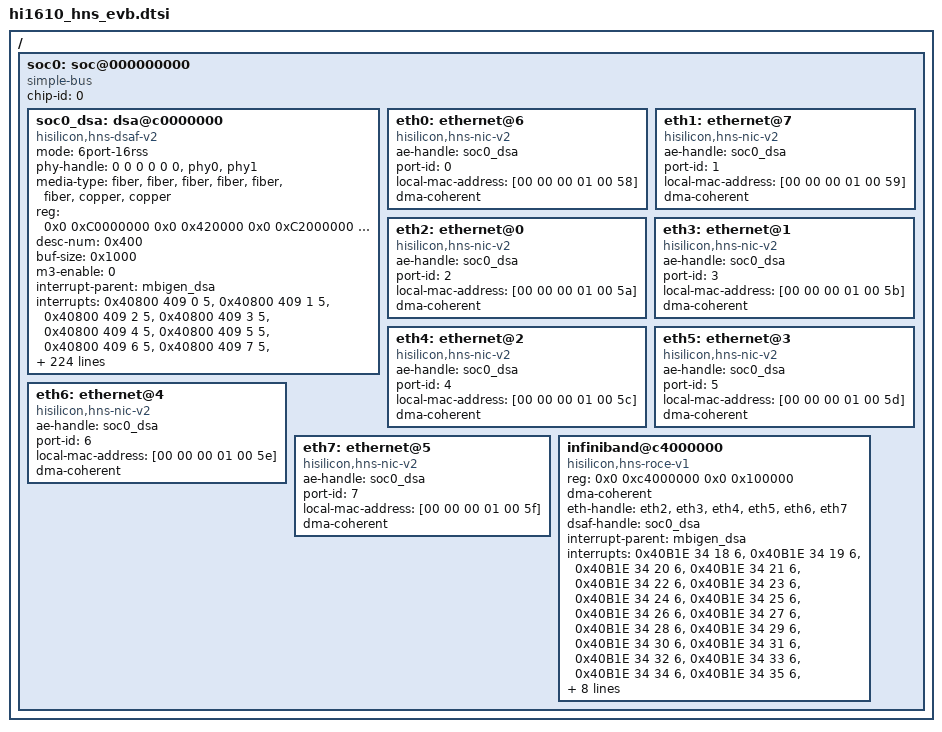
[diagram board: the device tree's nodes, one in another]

/*
 * dtsi file for Hisilicon Hi1610 hns driver
 */

/ {
	soc0: soc@000000000 {
		#address-cells = <2>;
		#size-cells = <2>;
		device_type = "soc";
		compatible = "simple-bus";
		ranges = <0x0 0x0 0x0 0x0 0x1 0x0>;
		chip-id = <0>;

		soc0_dsa: dsa@c0000000 {
			compatible = "hisilicon,hns-dsaf-v2";
			mode = "6port-16rss";
			phy-handle = <0 0 0 0 0 0 &phy0 &phy1>;
			media-type = "fiber", "fiber", "fiber", "fiber",
				"fiber", "fiber", "copper", "copper";
			reg = <0x0 0xC0000000 0x0 0x420000
				0x0 0xC2000000 0x0 0x300000
				0x0 0xc5000000 0x0 0x890000
				0x0 0xc7000000 0x0 0x60000
				0x0 0x78000010 0x0 0x100>;
			desc-num = <0x400>;
			buf-size = <0x1000>;
			m3-enable = <0>;

		interrupt-parent = <&mbigen_dsa>;
		interrupts =
		<0x40800 409 0 5>,<0x40800 409 1 5>,
		<0x40800 409 2 5>,<0x40800 409 3 5>,
		<0x40800 409 4 5>,<0x40800 409 5 5>,
		<0x40800 409 6 5>,<0x40800 409 7 5>,
		<0x40800 409 8 5>,<0x40800 409 9 5>,
		<0x40800 409 10 5>,<0x40800 409 11 5>,
		<0x40800 409 12 5>,
		<0x40800 409 0 7>,<0x40800 409 1 7>,
		<0x40800 409 2 7>,<0x40800 409 3 7>,
		<0x40800 409 4 7>,<0x40800 409 5 7>,
		<0x40800 409 6 7>,<0x40800 409 7 7>,
		<0x40800 409 8 7>,<0x40800 409 9 7>,
		<0x40800 409 10 7>,<0x40800 409 11 7>,
		/* index 25/26/27 ring0 tx/rx/doorbell*/
		<0x40800 409 0 8>,<0x40800 409 1 8>,<0x40800 409 2 8>,
		<0x40800 409 3 8>,<0x40800 409 4 8>,<0x40800 409 5 8>,
		<0x40800 409 6 8>,<0x40800 409 7 8>,<0x40800 409 8 8>,
		<0x40800 409 9 8>,<0x40800 409 10 8>,<0x40800 409 11 8>,
		<0x40800 409 12 8>,<0x40800 409 13 8>,<0x40800 409 14 8>,
		<0x40800 409 15 8>,<0x40800 409 16 8>,<0x40800 409 17 8>,
		<0x40800 409 18 8>,<0x40800 409 19 8>,<0x40800 409 20 8>,
		<0x40800 409 21 8>,<0x40800 409 22 8>,<0x40800 409 23 8>,
		<0x40800 409 24 8>,<0x40800 409 25 8>,<0x40800 409 26 8>,
		<0x40800 409 27 8>,<0x40800 409 28 8>,<0x40800 409 29 8>,
		<0x40800 409 30 8>,<0x40800 409 31 8>,<0x40800 409 32 8>,
		<0x40800 409 33 8>,<0x40800 409 34 8>,<0x40800 409 35 8>,
		<0x40800 409 36 8>,<0x40800 409 37 8>,<0x40800 409 38 8>,
		<0x40800 409 39 8>,<0x40800 409 40 8>,<0x40800 409 41 8>,
		<0x40800 409 42 8>,<0x40800 409 43 8>,<0x40800 409 44 8>,
		<0x40800 409 45 8>,<0x40800 409 46 8>,<0x40800 409 47 8>,
		<0x40800 409 48 8>,<0x40800 409 49 8>,<0x40800 409 50 8>,
		<0x40800 409 51 8>,<0x40800 409 52 8>,<0x40800 409 53 8>,
		<0x40800 409 54 8>,<0x40800 409 55 8>,<0x40800 409 56 8>,
		<0x40800 409 57 8>,<0x40800 409 58 8>,<0x40800 409 59 8>,
		<0x40800 409 60 8>,<0x40800 409 61 8>,<0x40800 409 62 8>,
		<0x40800 409 63 8>,<0x40800 409 64 8>,<0x40800 409 65 8>,
		<0x40800 409 66 8>,<0x40800 409 67 8>,<0x40800 409 68 8>,
		<0x40800 409 69 8>,<0x40800 409 70 8>,<0x40800 409 71 8>,
		<0x40800 409 72 8>,<0x40800 409 73 8>,<0x40800 409 74 8>,
		<0x40800 409 75 8>,<0x40800 409 76 8>,<0x40800 409 77 8>,
		<0x40800 409 78 8>,<0x40800 409 79 8>,<0x40800 409 80 8>,
		<0x40800 409 81 8>,<0x40800 409 82 8>,<0x40800 409 83 8>,
		<0x40800 409 84 8>,<0x40800 409 85 8>,<0x40800 409 86 8>,
		<0x40800 409 87 8>,<0x40800 409 88 8>,<0x40800 409 89 8>,
		<0x40800 409 90 8>,<0x40800 409 91 8>,<0x40800 409 92 8>,
		<0x40800 409 93 8>,<0x40800 409 94 8>,<0x40800 409 95 8>,
		<0x40800 409 96 8>,<0x40800 409 97 8>,<0x40800 409 98 8>,
		<0x40800 409 99 8>,<0x40800 409 100 8>,<0x40800 409 101 8>,
		<0x40800 409 102 8>,<0x40800 409 103 8>,<0x40800 409 104 8>,
		<0x40800 409 105 8>,<0x40800 409 106 8>,<0x40800 409 107 8>,
		<0x40800 409 108 8>,<0x40800 409 109 8>,<0x40800 409 110 8>,
		<0x40800 409 111 8>,<0x40800 409 112 8>,<0x40800 409 113 8>,
		<0x40800 409 114 8>,<0x40800 409 115 8>,<0x40800 409 116 8>,
		<0x40800 409 117 8>,<0x40800 409 118 8>,<0x40800 409 119 8>,
		<0x40800 409 120 8>,<0x40800 409 121 8>,<0x40800 409 122 8>,
		<0x40800 409 123 8>,<0x40800 409 124 8>,<0x40800 409 125 8>,
		<0x40800 409 126 8>,<0x40800 409 127 8>,<0x40800 409 0 9>,
		<0x40800 409 1 9>,<0x40800 409 2 9>,<0x40800 409 3 9>,
		<0x40800 409 4 9>,<0x40800 409 5 9>,<0x40800 409 6 9>,
		<0x40800 409 7 9>,<0x40800 409 8 9>,<0x40800 409 9 9>,
		<0x40800 409 10 9>,<0x40800 409 11 9>,<0x40800 409 12 9>,
		<0x40800 409 13 9>,<0x40800 409 14 9>,<0x40800 409 15 9>,
		<0x40800 409 16 9>,<0x40800 409 17 9>,<0x40800 409 18 9>,
		<0x40800 409 19 9>,<0x40800 409 20 9>,<0x40800 409 21 9>,
		<0x40800 409 22 9>,<0x40800 409 23 9>,<0x40800 409 24 9>,
		<0x40800 409 25 9>,<0x40800 409 26 9>,<0x40800 409 27 9>,
		<0x40800 409 28 9>,<0x40800 409 29 9>,<0x40800 409 30 9>,
		<0x40800 409 31 9>,<0x40800 409 32 9>,<0x40800 409 33 9>,
		<0x40800 409 34 9>,<0x40800 409 35 9>,<0x40800 409 36 9>,
		<0x40800 409 37 9>,<0x40800 409 38 9>,<0x40800 409 39 9>,
		<0x40800 409 40 9>,<0x40800 409 41 9>,<0x40800 409 42 9>,
		<0x40800 409 43 9>,<0x40800 409 44 9>,<0x40800 409 45 9>,
		<0x40800 409 46 9>,<0x40800 409 47 9>,<0x40800 409 48 9>,
		<0x40800 409 49 9>,<0x40800 409 50 9>,<0x40800 409 51 9>,
		<0x40800 409 52 9>,<0x40800 409 53 9>,<0x40800 409 54 9>,
		<0x40800 409 55 9>,<0x40800 409 56 9>,<0x40800 409 57 9>,
		<0x40800 409 58 9>,<0x40800 409 59 9>,<0x40800 409 60 9>,
		<0x40800 409 61 9>,<0x40800 409 62 9>,<0x40800 409 63 9>,
		<0x40800 409 64 9>,<0x40800 409 65 9>,<0x40800 409 66 9>,
		<0x40800 409 67 9>,<0x40800 409 68 9>,<0x40800 409 69 9>,
		<0x40800 409 70 9>,<0x40800 409 71 9>,<0x40800 409 72 9>,
		<0x40800 409 73 9>,<0x40800 409 74 9>,<0x40800 409 75 9>,
		<0x40800 409 76 9>,<0x40800 409 77 9>,<0x40800 409 78 9>,
		<0x40800 409 79 9>,<0x40800 409 80 9>,<0x40800 409 81 9>,
		<0x40800 409 82 9>,<0x40800 409 83 9>,<0x40800 409 84 9>,
		<0x40800 409 85 9>,<0x40800 409 86 9>,<0x40800 409 87 9>,
		<0x40800 409 88 9>,<0x40800 409 89 9>,<0x40800 409 90 9>,
		<0x40800 409 91 9>,<0x40800 409 92 9>,<0x40800 409 93 9>,
		<0x40800 409 94 9>,<0x40800 409 95 9>,<0x40800 409 96 9>,
		<0x40800 409 97 9>,<0x40800 409 98 9>,<0x40800 409 99 9>,
		<0x40800 409 100 9>,<0x40800 409 101 9>,<0x40800 409 102 9>,
		<0x40800 409 103 9>,<0x40800 409 104 9>,<0x40800 409 105 9>,
		<0x40800 409 106 9>,<0x40800 409 107 9>,<0x40800 409 108 9>,
		<0x40800 409 109 9>,<0x40800 409 110 9>,<0x40800 409 111 9>,
		<0x40800 409 112 9>,<0x40800 409 113 9>,<0x40800 409 114 9>,
		<0x40800 409 115 9>,<0x40800 409 116 9>,<0x40800 409 117 9>,
		<0x40800 409 118 9>,<0x40800 409 119 9>,<0x40800 409 120 9>,
		<0x40800 409 121 9>,<0x40800 409 122 9>,<0x40800 409 123 9>,
		<0x40800 409 124 9>,<0x40800 409 125 9>,<0x40800 409 126 9>,
		<0x40800 409 127 9>,<0x40800 409 0 10>,<0x40800 409 1 10>,
		<0x40800 409 2 10>,<0x40800 409 3 10>,<0x40800 409 4 10>,
		<0x40800 409 5 10>,<0x40800 409 6 10>,<0x40800 409 7 10>,
		<0x40800 409 8 10>,<0x40800 409 9 10>,<0x40800 409 10 10>,
		<0x40800 409 11 10>,<0x40800 409 12 10>,<0x40800 409 13 10>,
		<0x40800 409 14 10>,<0x40800 409 15 10>,<0x40800 409 16 10>,
		<0x40800 409 17 10>,<0x40800 409 18 10>,<0x40800 409 19 10>,
		<0x40800 409 20 10>,<0x40800 409 21 10>,<0x40800 409 22 10>,
		<0x40800 409 23 10>,<0x40800 409 24 10>,<0x40800 409 25 10>,
		<0x40800 409 26 10>,<0x40800 409 27 10>,<0x40800 409 28 10>,
		<0x40800 409 29 10>,<0x40800 409 30 10>,<0x40800 409 31 10>,
		<0x40800 409 32 10>,<0x40800 409 33 10>,<0x40800 409 34 10>,
		<0x40800 409 35 10>,<0x40800 409 36 10>,<0x40800 409 37 10>,
		<0x40800 409 38 10>,<0x40800 409 39 10>,<0x40800 409 40 10>,
		<0x40800 409 41 10>,<0x40800 409 42 10>,<0x40800 409 43 10>,
		<0x40800 409 44 10>,<0x40800 409 45 10>,<0x40800 409 46 10>,
		<0x40800 409 47 10>,<0x40800 409 48 10>,<0x40800 409 49 10>,
		<0x40800 409 50 10>,<0x40800 409 51 10>,<0x40800 409 52 10>,
		<0x40800 409 53 10>,<0x40800 409 54 10>,<0x40800 409 55 10>,
		<0x40800 409 56 10>,<0x40800 409 57 10>,<0x40800 409 58 10>,
		<0x40800 409 59 10>,<0x40800 409 60 10>,<0x40800 409 61 10>,
		<0x40800 409 62 10>,<0x40800 409 63 10>,<0x40800 409 64 10>,
		<0x40800 409 65 10>,<0x40800 409 66 10>,<0x40800 409 67 10>,
		<0x40800 409 68 10>,<0x40800 409 69 10>,<0x40800 409 70 10>,
		<0x40800 409 71 10>,<0x40800 409 72 10>,<0x40800 409 73 10>,
		<0x40800 409 74 10>,<0x40800 409 75 10>,<0x40800 409 76 10>,
		<0x40800 409 77 10>,<0x40800 409 78 10>,<0x40800 409 79 10>,
		<0x40800 409 80 10>,<0x40800 409 81 10>,<0x40800 409 82 10>,
		<0x40800 409 83 10>,<0x40800 409 84 10>,<0x40800 409 85 10>,
		<0x40800 409 86 10>,<0x40800 409 87 10>,<0x40800 409 88 10>,
		<0x40800 409 89 10>,<0x40800 409 90 10>,<0x40800 409 91 10>,
		<0x40800 409 92 10>,<0x40800 409 93 10>,<0x40800 409 94 10>,
		<0x40800 409 95 10>,<0x40800 409 96 10>,<0x40800 409 97 10>,
		<0x40800 409 98 10>,<0x40800 409 99 10>,<0x40800 409 100 10>,
		<0x40800 409 101 10>,<0x40800 409 102 10>,<0x40800 409 103 10>,
		<0x40800 409 104 10>,<0x40800 409 105 10>,<0x40800 409 106 10>,
		<0x40800 409 107 10>,<0x40800 409 108 10>,<0x40800 409 109 10>,
		<0x40800 409 110 10>,<0x40800 409 111 10>,<0x40800 409 112 10>,
		<0x40800 409 113 10>,<0x40800 409 114 10>,<0x40800 409 115 10>,
		<0x40800 409 116 10>,<0x40800 409 117 10>,<0x40800 409 118 10>,
		<0x40800 409 119 10>,<0x40800 409 120 10>,<0x40800 409 121 10>,
		<0x40800 409 122 10>,<0x40800 409 123 10>,<0x40800 409 124 10>,
		<0x40800 409 125 10>,<0x40800 409 126 10>,<0x40800 409 127 10>,
		/* index = 409 debug0 tx/rx */
		<0x40b1c 9 0 6>,<0x40b1c 9 1 6>,
		<0x40b1c 9 2 6>,<0x40b1c 9 3 6>,
		<0x40b1c 9 4 6>,<0x40b1c 9 5 6>,
		<0x40b1c 9 6 6>,<0x40b1c 9 7 6>,
		<0x40b1c 9 8 6>,
		/* index = 418 debug1 tx/rx */
		<0x40b1d 9 9 6>,<0x40b1d 9 10 6>,
		<0x40b1d 9 11 6>,<0x40b1d 9 12 6>,
		<0x40b1d 9 13 6>,<0x40b1d 9 14 6>,
		<0x40b1d 9 15 6>,<0x40b1d 9 16 6>,
		<0x40b1d 9 17 6>,
		/* xbar int index=427 */
		<0x40b1f 18 51 6>,<0x40b1f 18 52 6>,
		<0x40b1f 18 53 6>,<0x40b1f 18 54 6>,
		<0x40b1f 18 55 6>,<0x40b1f 18 56 6>,
		<0x40b1f 18 57 6>,<0x40b1f 18 58 6>,
		<0x40b1f 18 59 6>,<0x40b1f 18 60 6>,
		<0x40b1f 18 61 6>,<0x40b1f 18 62 6>,
		<0x40b1f 18 63 6>,<0x40b1f 18 64 6>,
		<0x40b1f 18 65 6>,<0x40b1f 18 66 6>,
		<0x40b1f 18 67 6>,<0x40b1f 18 68 6>,
		<0x40881 12 13 5>, /* GE0 int index=445 */
		<0x40881 12 14 5>,
		<0x40881 12 15 5>,
		<0x40881 12 16 5>,
		<0x40881 12 17 5>,
		<0x40881 12 18 5>,
		<0x40881 12 19 5>, /* XGE0 int index=451 */
		<0x40881 12 20 5>,
		<0x40881 12 21 5>,
		<0x40881 12 22 5>,
		<0x40881 12 23 5>,
		<0x40881 12 24 5>;
			dma-coherent;
		};

		eth0:ethernet@6 {
			compatible = "hisilicon,hns-nic-v2";
			ae-handle = <&soc0_dsa>;
			port-id = <0>;
			local-mac-address = [00 00 00 01 00 58];
			dma-coherent;
		};

		eth1:ethernet@7 {
			compatible = "hisilicon,hns-nic-v2";
			ae-handle = <&soc0_dsa>;
			port-id = <1>;
			local-mac-address = [00 00 00 01 00 59];
			dma-coherent;
		};

		eth2:ethernet@0 {
			compatible = "hisilicon,hns-nic-v2";
			ae-handle = <&soc0_dsa>;
			port-id = <2>;
			local-mac-address = [00 00 00 01 00 5a];
			dma-coherent;
		};

		eth3:ethernet@1 {
			compatible = "hisilicon,hns-nic-v2";
			ae-handle = <&soc0_dsa>;
			port-id = <3>;
			local-mac-address = [00 00 00 01 00 5b];
			dma-coherent;
		};

		eth4:ethernet@2 {
			compatible = "hisilicon,hns-nic-v2";
			ae-handle = <&soc0_dsa>;
			port-id = <4>;
			local-mac-address = [00 00 00 01 00 5c];
			dma-coherent;
		};

		eth5:ethernet@3 {
			compatible = "hisilicon,hns-nic-v2";
			ae-handle = <&soc0_dsa>;
			port-id = <5>;
			local-mac-address = [00 00 00 01 00 5d];
			dma-coherent;
		};

		eth6:ethernet@4 {
			compatible = "hisilicon,hns-nic-v2";
			ae-handle = <&soc0_dsa>;
			port-id = <6>;
			local-mac-address = [00 00 00 01 00 5e];
			dma-coherent;
		};

		eth7:ethernet@5 {
			compatible = "hisilicon,hns-nic-v2";
			ae-handle = <&soc0_dsa>;
			port-id = <7>;
			local-mac-address = [00 00 00 01 00 5f];
			dma-coherent;
		};

		infiniband@c4000000 {
			compatible = "hisilicon,hns-roce-v1";
			reg = <0x0 0xc4000000 0x0 0x100000>;
			dma-coherent;
			eth-handle = <&eth2 &eth3 &eth4 &eth5 &eth6 &eth7>;
			dsaf-handle = <&soc0_dsa>;
			#address-cells = <2>;
			#size-cells = <2>;
			interrupt-parent = <&mbigen_dsa>;
			interrupts = <0x40B1E 34 18 6>,
					<0x40B1E 34 19 6>,
					<0x40B1E 34 20 6>,
					<0x40B1E 34 21 6>,
					<0x40B1E 34 22 6>,
					<0x40B1E 34 23 6>,
					<0x40B1E 34 24 6>,
					<0x40B1E 34 25 6>,
					<0x40B1E 34 26 6>,
					<0x40B1E 34 27 6>,
					<0x40B1E 34 28 6>,
					<0x40B1E 34 29 6>,
					<0x40B1E 34 30 6>,
					<0x40B1E 34 31 6>,
					<0x40B1E 34 32 6>,
					<0x40B1E 34 33 6>,
					<0x40B1E 34 34 6>,
					<0x40B1E 34 35 6>,
					<0x40B1E 34 36 6>,
					<0x40B1E 34 37 6>,
					<0x40B1E 34 38 6>,
					<0x40B1E 34 39 6>,
					<0x40B1E 34 40 6>,
					<0x40B1E 34 41 6>,
					<0x40B1E 34 42 6>,
					<0x40B1E 34 43 6>,
					<0x40B1E 34 44 6>,
					<0x40B1E 34 45 6>,
					<0x40B1E 34 46 6>,
					<0x40B1E 34 47 6>,
					<0x40B1E 34 48 6>,
					<0x40B1E 34 49 6>,
					<0x40B1E 34 50 6>,
					<0x40B1E 34 81 6>;
			interrupt-names = "hns-roce-comp-0",
					"hns-roce-comp-1",
					"hns-roce-comp-2",
					"hns-roce-comp-3",
					"hns-roce-comp-4",
					"hns-roce-comp-5",
					"hns-roce-comp-6",
					"hns-roce-comp-7",
					"hns-roce-comp-8",
					"hns-roce-comp-9",
					"hns-roce-comp-10",
					"hns-roce-comp-11",
					"hns-roce-comp-12",
					"hns-roce-comp-13",
					"hns-roce-comp-14",
					"hns-roce-comp-15",
					"hns-roce-comp-16",
					"hns-roce-comp-17",
					"hns-roce-comp-18",
					"hns-roce-comp-19",
					"hns-roce-comp-20",
					"hns-roce-comp-21",
					"hns-roce-comp-22",
					"hns-roce-comp-23",
					"hns-roce-comp-24",
					"hns-roce-comp-25",
					"hns-roce-comp-26",
					"hns-roce-comp-27",
					"hns-roce-comp-28",
					"hns-roce-comp-29",
					"hns-roce-comp-30",
					"hns-roce-comp-31",
					"hns-roce-async",
					"hns-roce-common";
		};
	};
};
